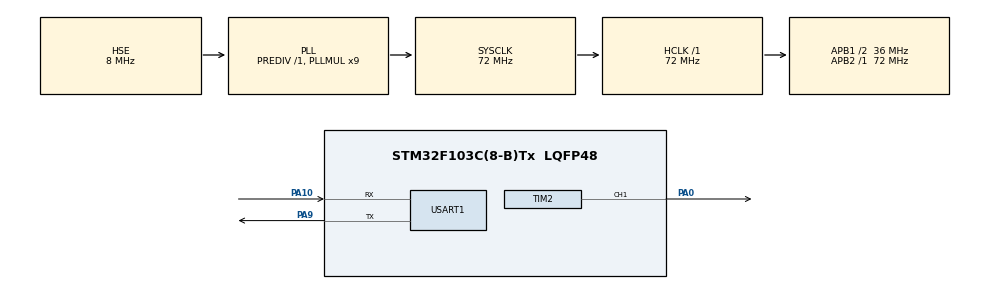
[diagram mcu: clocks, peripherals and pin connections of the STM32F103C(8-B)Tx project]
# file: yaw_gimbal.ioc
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Mcu.Family=STM32F1
Mcu.Name=STM32F103C(8-B)Tx
Mcu.Package=LQFP48
NVIC.PriorityGroup=NVIC_PRIORITYGROUP_4
NVIC.USART1_IRQn=true\:0\:0\:false\:false\:true\:true\:true\:true
PA0-WKUP.Signal=S_TIM2_CH1_ETR
PA10.Mode=Asynchronous
PA10.Signal=USART1_RX
PA13.Mode=Serial_Wire
PA13.Signal=SYS_JTMS-SWDIO
PA14.Mode=Serial_Wire
PA14.Signal=SYS_JTCK-SWCLK
PA9.Mode=Asynchronous
PA9.Signal=USART1_TX
PD0-OSC_IN.Mode=HSE-External-Oscillator
PD0-OSC_IN.Signal=RCC_OSC_IN
PD1-OSC_OUT.Mode=HSE-External-Oscillator
PD1-OSC_OUT.Signal=RCC_OSC_OUT
ProjectManager.HeapSize=0x200
ProjectManager.StackSize=0x400
ProjectManager.TargetToolchain=Makefile
RCC.AHBFreq_Value=72000000
RCC.APB1CLKDivider=RCC_HCLK_DIV2
RCC.APB1Freq_Value=36000000
RCC.APB1TimFreq_Value=72000000
RCC.APB2Freq_Value=72000000
RCC.APB2TimFreq_Value=72000000
RCC.HCLKFreq_Value=72000000
RCC.PLLMUL=RCC_PLL_MUL9
RCC.PLLSourceVirtual=RCC_PLLSOURCE_HSE
RCC.SYSCLKFreq_VALUE=72000000
RCC.SYSCLKSource=RCC_SYSCLKSOURCE_PLLCLK
RCC.USBFreq_Value=72000000
SH.S_TIM2_CH1_ETR.0=TIM2_CH1,PWM Generation1 CH1
TIM2.Channel-PWM\ Generation1\ CH1=TIM_CHANNEL_1
USART1.VirtualMode=VM_ASYNC
board=custom

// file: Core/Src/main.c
/* USER CODE BEGIN Header */
/**
  ******************************************************************************
  * @file           : main.c
  * @brief          : Main program body
  ******************************************************************************
  * @attention
  *
  * Copyright (c) 2026 STMicroelectronics.
  * All rights reserved.
  *
  * This software is licensed under terms that can be found in the LICENSE file
  * in the root directory of this software component.
  * If no LICENSE file comes with this software, it is provided AS-IS.
  *
  ******************************************************************************
  */
/* USER CODE END Header */
#include "main.h"
#include "tim.h"
#include "usart.h"
#include "gpio.h"

/* USER CODE BEGIN Includes */
#include <string.h>
#include <string.h>
/* USER CODE END Includes */

/* USER CODE BEGIN PV */
/* ---- 串口接收缓冲 ---- */
uint8_t  rx_byte;              /* UART 中断接收的单字节 */
uint8_t  rx_buf[32];           /* 帧缓冲 */
uint8_t  rx_idx = 0;           /* 缓冲写指针 */

/* ---- 解析结果（volatile：中断里写，主循环里读）---- */
volatile float   g_yaw    = 0.0f;    /* 目标水平角（度）*/
volatile float   g_pitch  = 0.0f;    /* 目标垂直角（度）*/
volatile float   g_dist   = 0.0f;    /* 距离（米）*/
volatile uint8_t g_fire   = 0;
volatile uint8_t g_status = 0;
/* USER CODE END PV */

void SystemClock_Config(void);
/* USER CODE BEGIN PFP */
static uint32_t servo_pulse(float angle_deg);   /* while 里用到，定义在文件末尾 */
/* USER CODE END PFP */

/* USER CODE END 0 */

int main(void)
{

  /* MCU Configuration--------------------------------------------------------*/

  /* Reset of all peripherals, Initializes the Flash interface and the Systick. */
  HAL_Init();

  /* Configure the system clock */
  SystemClock_Config();

  /* Initialize all configured peripherals */
  MX_GPIO_Init();
  MX_TIM2_Init();
  MX_USART1_UART_Init();
  /* USER CODE BEGIN 2 */
  /* 启动 PWM（50Hz，中位 1.5ms）*/
  HAL_TIM_PWM_Start(&htim2, TIM_CHANNEL_1);

  /* 启动 UART 中断接收（单字节模式）*/
  HAL_UART_Receive_IT(&huart1, &rx_byte, 1);
/* USER CODE END 2 */
HAL_TIM_PWM_Start(&htim2, TIM_CHANNEL_1);
HAL_UART_Receive_IT(&huart1, &rx_byte, 1);
  /* USER CODE END 2 */

  /* Infinite loop */
  while (1)
  {

    /* USER CODE BEGIN 3 */
    __HAL_TIM_SET_COMPARE(&htim2, TIM_CHANNEL_1, servo_pulse(90.0f + g_yaw));
    HAL_Delay(5);
  }
  /* USER CODE END 3 */
}

void SystemClock_Config(void)
{
  RCC_OscInitTypeDef RCC_OscInitStruct = {0};
  RCC_ClkInitTypeDef RCC_ClkInitStruct = {0};

  /** Initializes the RCC Oscillators according to the specified parameters
  * in the RCC_OscInitTypeDef structure.
  */
  RCC_OscInitStruct.OscillatorType = RCC_OSCILLATORTYPE_HSE;
  RCC_OscInitStruct.HSEState = RCC_HSE_ON;
  RCC_OscInitStruct.HSEPredivValue = RCC_HSE_PREDIV_DIV1;
  RCC_OscInitStruct.HSIState = RCC_HSI_ON;
  RCC_OscInitStruct.PLL.PLLState = RCC_PLL_ON;
  RCC_OscInitStruct.PLL.PLLSource = RCC_PLLSOURCE_HSE;
  RCC_OscInitStruct.PLL.PLLMUL = RCC_PLL_MUL9;
  if (HAL_RCC_OscConfig(&RCC_OscInitStruct) != HAL_OK)
  {
    Error_Handler();
  }

  /** Initializes the CPU, AHB and APB buses clocks
  */
  RCC_ClkInitStruct.ClockType = RCC_CLOCKTYPE_HCLK|RCC_CLOCKTYPE_SYSCLK
                              |RCC_CLOCKTYPE_PCLK1|RCC_CLOCKTYPE_PCLK2;
  RCC_ClkInitStruct.SYSCLKSource = RCC_SYSCLKSOURCE_PLLCLK;
  RCC_ClkInitStruct.AHBCLKDivider = RCC_SYSCLK_DIV1;
  RCC_ClkInitStruct.APB1CLKDivider = RCC_HCLK_DIV2;
  RCC_ClkInitStruct.APB2CLKDivider = RCC_HCLK_DIV1;

  if (HAL_RCC_ClockConfig(&RCC_ClkInitStruct, FLASH_LATENCY_2) != HAL_OK)
  {
    Error_Handler();
  }
}

/* USER CODE BEGIN 4 */
static uint32_t servo_pulse(float a) {
    if (a < 0) a = 0;
    if (a > 180) a = 180;
    return (uint32_t)(500.0f + a * 11.111f);
}

void HAL_UART_RxCpltCallback(UART_HandleTypeDef *huart) {
    if (huart->Instance != USART1) return;
    rx_buf[rx_idx++] = rx_byte;
    if (rx_idx >= 2 && rx_buf[rx_idx-2]==0xAA && rx_buf[rx_idx-1]==0x55) {
        rx_idx = 2;
    } else if (rx_idx >= 18) {
        if (rx_buf[17] == 0x0D) {
            uint8_t sum = 0;
            for (int i = 2; i < 16; i++) sum += rx_buf[i];
            if (sum == rx_buf[16]) {
                float yaw;
                memcpy(&yaw, &rx_buf[2], 4);
                g_yaw = yaw;
            }
        }
        rx_idx = 0;
    }
    HAL_UART_Receive_IT(huart, &rx_byte, 1);
}
/* USER CODE END 4 */

void Error_Handler(void)
{
  __disable_irq();
  while (1)
  {
  }
}
